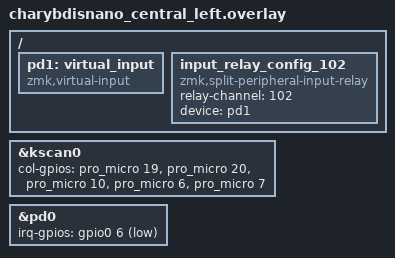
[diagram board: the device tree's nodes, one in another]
/*
 * Copyright (c) 2020 ZMK Contributors
 *
 * SPDX-License-Identifier: MIT
 */
 
#include "charybdisnano.dtsi"


&kscan0 {
	col-gpios
		= <&pro_micro 19 GPIO_ACTIVE_HIGH>
		, <&pro_micro 20 GPIO_ACTIVE_HIGH>
		, <&pro_micro 10 GPIO_ACTIVE_HIGH>
		, <&pro_micro 6 GPIO_ACTIVE_HIGH>
		, <&pro_micro 7 GPIO_ACTIVE_HIGH>
		;
};

#include "charybdisnano_trackball.dtsi"

/* enable &pd0 on central. typical input device for zephyr input subsystem. */
/* NOTE 1: use the same device alias (&pd0) on central and peripheral(s) is alright. */
&pd0 {
  status = "okay";
  irq-gpios = <&gpio0 6 (GPIO_ACTIVE_LOW | GPIO_PULL_UP)>;
};

/ {
	/* define virtual input, will be resurrected for emitting input event */
	/* NOTE: set `device = <&pd1>` in `zmk,input-listener` */
	pd1: virtual_input {
		compatible = "zmk,virtual-input";
	};
};

/ {
	/* for central side, define (relay-channel)-to-(virtual-input) mapping */
	input_relay_config_102 {
		compatible = "zmk,split-peripheral-input-relay";
		
		/* channel id, used to filter incoming annotated input event from split peripheral */
		/* NOTE: should matching relay-channel on peripheral overlay */
		relay-channel = <102>;

		/* virtual input device on central, which used to emit input event as an agent device */
		device = <&pd1>;
	};
};

#define INPUT_EV_KEY 0x01               /**< Key event */
#define INPUT_EV_REL 0x02               /**< Relative coordinate event */
#define INPUT_EV_ABS 0x03               /**< Absolute coordinate event */
#define INPUT_EV_MSC 0x04               /**< Miscellaneous event */
#define INPUT_EV_VENDOR_START 0xf0      /**< Vendor specific event start */
#define INPUT_EV_VENDOR_STOP 0xff       /**< Vendor specific event stop */

#define INPUT_REL_X 0x00                /**< Relative X coordinate */
#define INPUT_REL_Y 0x01                /**< Relative Y coordinate */
#define INPUT_REL_WHEEL 0x08            /**< Relative wheel coordinate */
#define INPUT_REL_HWHEEL 0x06           /**< Relative horizontal wheel coordinate */
#define INPUT_REL_MISC 0x09             /**< Relative misc coordinate */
